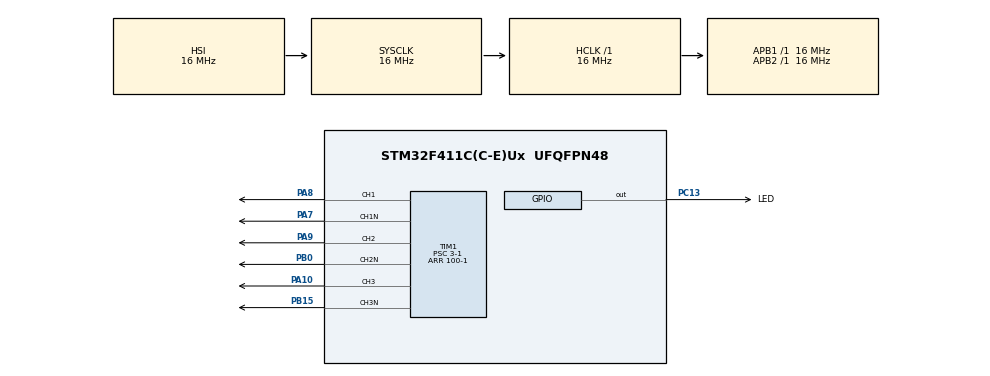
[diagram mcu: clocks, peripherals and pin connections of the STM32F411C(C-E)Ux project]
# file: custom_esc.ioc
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Mcu.Family=STM32F4
Mcu.Name=STM32F411C(C-E)Ux
Mcu.Package=UFQFPN48
NVIC.PriorityGroup=NVIC_PRIORITYGROUP_4
NVIC.TIM1_TRG_COM_TIM11_IRQn=true\:0\:0\:false\:false\:true\:true\:true\:true
PA10.Signal=S_TIM1_CH3
PA7.Mode=PWM Generation1 CH1 CH1N
PA7.Signal=TIM1_CH1N
PA8.Signal=S_TIM1_CH1
PA9.Signal=S_TIM1_CH2
PB0.Mode=PWM Generation2 CH2 CH2N
PB0.Signal=TIM1_CH2N
PB15.Mode=PWM Generation3 CH3 CH3N
PB15.Signal=TIM1_CH3N
PC13-ANTI_TAMP.GPIO_Label=LED
PC13-ANTI_TAMP.Signal=GPIO_Output
ProjectManager.HeapSize=0x200
ProjectManager.StackSize=0x400
ProjectManager.TargetToolchain=STM32CubeIDE
RCC.AHBFreq_Value=16000000
RCC.APB1Freq_Value=16000000
RCC.APB2Freq_Value=16000000
RCC.CortexFreq_Value=16000000
RCC.HSE_VALUE=25000000
RCC.HSI_VALUE=16000000
RCC.LSE_VALUE=32768
RCC.SYSCLKFreq_VALUE=16000000
RCC.VCOOutputFreq_Value=192000000
SH.S_TIM1_CH1.0=TIM1_CH1,PWM Generation1 CH1 CH1N
SH.S_TIM1_CH2.0=TIM1_CH2,PWM Generation2 CH2 CH2N
SH.S_TIM1_CH3.0=TIM1_CH3,PWM Generation3 CH3 CH3N
TIM1.AutoReloadPreload=TIM_AUTORELOAD_PRELOAD_ENABLE
TIM1.BreakState=TIM_BREAK_DISABLE
TIM1.Channel-PWM\ Generation1\ CH1\ CH1N=TIM_CHANNEL_1
TIM1.Channel-PWM\ Generation2\ CH2\ CH2N=TIM_CHANNEL_2
TIM1.Channel-PWM\ Generation3\ CH3\ CH3N=TIM_CHANNEL_3
TIM1.DeadTime=32
TIM1.OCIdleState_1=TIM_OCIDLESTATE_SET
TIM1.OCIdleState_2=TIM_OCIDLESTATE_SET
TIM1.OCIdleState_3=TIM_OCIDLESTATE_SET
TIM1.OCNIdleState_1=TIM_OCNIDLESTATE_RESET
TIM1.OCNPolarity_1=TIM_OCNPOLARITY_HIGH
TIM1.OCNPolarity_2=TIM_OCNPOLARITY_HIGH
TIM1.OCNPolarity_3=TIM_OCNPOLARITY_HIGH
TIM1.OCPolarity_1=TIM_OCPOLARITY_LOW
TIM1.OCPolarity_2=TIM_OCPOLARITY_LOW
TIM1.OCPolarity_3=TIM_OCPOLARITY_LOW
TIM1.OffStateIDLEMode=TIM_OSSI_ENABLE
TIM1.OffStateRunMode=TIM_OSSR_ENABLE
TIM1.Period=100-1
TIM1.Prescaler=3-1
TIM1.Pulse-PWM\ Generation1\ CH1\ CH1N=50-1
TIM1.Pulse-PWM\ Generation2\ CH2\ CH2N=50-1
TIM1.Pulse-PWM\ Generation3\ CH3\ CH3N=50-1
TIM11.Channel=TIM_CHANNEL_1
TIM11.Period=700-1
TIM11.Prescaler=64-1
VP_TIM11_VS_ClockSourceINT.Mode=Enable_Timer
VP_TIM11_VS_no_output1.Mode=Output Compare1 No Output
board=custom

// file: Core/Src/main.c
/* USER CODE BEGIN Header */
/**
  ******************************************************************************
  * @file           : main.c
  * @brief          : Main program body
  ******************************************************************************
  * @attention
  *
  * Copyright (c) 2026 STMicroelectronics.
  * All rights reserved.
  *
  * This software is licensed under terms that can be found in the LICENSE file
  * in the root directory of this software component.
  * If no LICENSE file comes with this software, it is provided AS-IS.
  *
  ******************************************************************************
  */
/* USER CODE END Header */
#include "main.h"

/* USER CODE BEGIN Includes */
#include "esc_main.h"
/* USER CODE END Includes */

TIM_HandleTypeDef htim1;
TIM_HandleTypeDef htim11;

void SystemClock_Config(void);
static void MX_GPIO_Init(void);
static void MX_TIM1_Init(void);
static void MX_TIM11_Init(void);

int main(void)
{

  /* MCU Configuration--------------------------------------------------------*/

  /* Reset of all peripherals, Initializes the Flash interface and the Systick. */
  HAL_Init();

  /* Configure the system clock */
  SystemClock_Config();

  /* Initialize all configured peripherals */
  MX_GPIO_Init();
  MX_TIM1_Init();
  MX_TIM11_Init();
  /* USER CODE BEGIN 2 */
  esc_main(); //provides the infinite loop, the loop below should never be entered
  /* USER CODE END 2 */

  /* Infinite loop */
  while (1)
  {

  }
}

void SystemClock_Config(void)
{
  RCC_OscInitTypeDef RCC_OscInitStruct = {0};
  RCC_ClkInitTypeDef RCC_ClkInitStruct = {0};

  /** Configure the main internal regulator output voltage
  */
  __HAL_RCC_PWR_CLK_ENABLE();
  __HAL_PWR_VOLTAGESCALING_CONFIG(PWR_REGULATOR_VOLTAGE_SCALE1);

  /** Initializes the RCC Oscillators according to the specified parameters
  * in the RCC_OscInitTypeDef structure.
  */
  RCC_OscInitStruct.OscillatorType = RCC_OSCILLATORTYPE_HSI;
  RCC_OscInitStruct.HSIState = RCC_HSI_ON;
  RCC_OscInitStruct.HSICalibrationValue = RCC_HSICALIBRATION_DEFAULT;
  RCC_OscInitStruct.PLL.PLLState = RCC_PLL_NONE;
  if (HAL_RCC_OscConfig(&RCC_OscInitStruct) != HAL_OK)
  {
    Error_Handler();
  }

  /** Initializes the CPU, AHB and APB buses clocks
  */
  RCC_ClkInitStruct.ClockType = RCC_CLOCKTYPE_HCLK|RCC_CLOCKTYPE_SYSCLK
                              |RCC_CLOCKTYPE_PCLK1|RCC_CLOCKTYPE_PCLK2;
  RCC_ClkInitStruct.SYSCLKSource = RCC_SYSCLKSOURCE_HSI;
  RCC_ClkInitStruct.AHBCLKDivider = RCC_SYSCLK_DIV1;
  RCC_ClkInitStruct.APB1CLKDivider = RCC_HCLK_DIV1;
  RCC_ClkInitStruct.APB2CLKDivider = RCC_HCLK_DIV1;

  if (HAL_RCC_ClockConfig(&RCC_ClkInitStruct, FLASH_LATENCY_0) != HAL_OK)
  {
    Error_Handler();
  }
}

static void MX_TIM1_Init(void)
{

  TIM_MasterConfigTypeDef sMasterConfig = {0};
  TIM_OC_InitTypeDef sConfigOC = {0};
  TIM_BreakDeadTimeConfigTypeDef sBreakDeadTimeConfig = {0};

  htim1.Instance = TIM1;
  htim1.Init.Prescaler = 3-1;
  htim1.Init.CounterMode = TIM_COUNTERMODE_UP;
  htim1.Init.Period = 100-1;
  htim1.Init.ClockDivision = TIM_CLOCKDIVISION_DIV1;
  htim1.Init.RepetitionCounter = 0;
  htim1.Init.AutoReloadPreload = TIM_AUTORELOAD_PRELOAD_ENABLE;
  if (HAL_TIM_PWM_Init(&htim1) != HAL_OK)
  {
    Error_Handler();
  }
  sMasterConfig.MasterOutputTrigger = TIM_TRGO_RESET;
  sMasterConfig.MasterSlaveMode = TIM_MASTERSLAVEMODE_DISABLE;
  if (HAL_TIMEx_MasterConfigSynchronization(&htim1, &sMasterConfig) != HAL_OK)
  {
    Error_Handler();
  }
  sConfigOC.OCMode = TIM_OCMODE_PWM1;
  sConfigOC.Pulse = 50-1;
  sConfigOC.OCPolarity = TIM_OCPOLARITY_LOW;
  sConfigOC.OCNPolarity = TIM_OCNPOLARITY_HIGH;
  sConfigOC.OCFastMode = TIM_OCFAST_DISABLE;
  sConfigOC.OCIdleState = TIM_OCIDLESTATE_SET;
  sConfigOC.OCNIdleState = TIM_OCNIDLESTATE_RESET;
  if (HAL_TIM_PWM_ConfigChannel(&htim1, &sConfigOC, TIM_CHANNEL_1) != HAL_OK)
  {
    Error_Handler();
  }
  if (HAL_TIM_PWM_ConfigChannel(&htim1, &sConfigOC, TIM_CHANNEL_2) != HAL_OK)
  {
    Error_Handler();
  }
  if (HAL_TIM_PWM_ConfigChannel(&htim1, &sConfigOC, TIM_CHANNEL_3) != HAL_OK)
  {
    Error_Handler();
  }
  sBreakDeadTimeConfig.OffStateRunMode = TIM_OSSR_ENABLE;
  sBreakDeadTimeConfig.OffStateIDLEMode = TIM_OSSI_ENABLE;
  sBreakDeadTimeConfig.LockLevel = TIM_LOCKLEVEL_OFF;
  sBreakDeadTimeConfig.DeadTime = 32;
  sBreakDeadTimeConfig.BreakState = TIM_BREAK_DISABLE;
  sBreakDeadTimeConfig.BreakPolarity = TIM_BREAKPOLARITY_HIGH;
  sBreakDeadTimeConfig.AutomaticOutput = TIM_AUTOMATICOUTPUT_DISABLE;
  if (HAL_TIMEx_ConfigBreakDeadTime(&htim1, &sBreakDeadTimeConfig) != HAL_OK)
  {
    Error_Handler();
  }
  HAL_TIM_MspPostInit(&htim1);

}

static void MX_TIM11_Init(void)
{

  TIM_OC_InitTypeDef sConfigOC = {0};

  htim11.Instance = TIM11;
  htim11.Init.Prescaler = 64-1;
  htim11.Init.CounterMode = TIM_COUNTERMODE_UP;
  htim11.Init.Period = 700-1;
  htim11.Init.ClockDivision = TIM_CLOCKDIVISION_DIV1;
  htim11.Init.AutoReloadPreload = TIM_AUTORELOAD_PRELOAD_DISABLE;
  if (HAL_TIM_Base_Init(&htim11) != HAL_OK)
  {
    Error_Handler();
  }
  if (HAL_TIM_OC_Init(&htim11) != HAL_OK)
  {
    Error_Handler();
  }
  sConfigOC.OCMode = TIM_OCMODE_TIMING;
  sConfigOC.Pulse = 0;
  sConfigOC.OCPolarity = TIM_OCPOLARITY_HIGH;
  sConfigOC.OCFastMode = TIM_OCFAST_DISABLE;
  if (HAL_TIM_OC_ConfigChannel(&htim11, &sConfigOC, TIM_CHANNEL_1) != HAL_OK)
  {
    Error_Handler();
  }

}

static void MX_GPIO_Init(void)
{
  GPIO_InitTypeDef GPIO_InitStruct = {0};

  /* GPIO Ports Clock Enable */
  __HAL_RCC_GPIOC_CLK_ENABLE();
  __HAL_RCC_GPIOA_CLK_ENABLE();
  __HAL_RCC_GPIOB_CLK_ENABLE();

  /*Configure GPIO pin Output Level */
  HAL_GPIO_WritePin(LED_GPIO_Port, LED_Pin, GPIO_PIN_RESET);

  /*Configure GPIO pin : LED_Pin */
  GPIO_InitStruct.Pin = LED_Pin;
  GPIO_InitStruct.Mode = GPIO_MODE_OUTPUT_PP;
  GPIO_InitStruct.Pull = GPIO_NOPULL;
  GPIO_InitStruct.Speed = GPIO_SPEED_FREQ_LOW;
  HAL_GPIO_Init(LED_GPIO_Port, &GPIO_InitStruct);

}

void Error_Handler(void)
{
  __disable_irq();
  while (1)
  {
  }
}
